# nrf54h20_engb_application register map
Vendor: Nordic Semiconductor; Series: nRF54h; File version: 1
CPU: CM33 r0p4, little endian, MPU, FPU, 3 interrupt priority bits, 480 interrupts, 8 SAU regions
Registers are 32-bit, read-write, reset 0x0 unless marked. A register's access mark holds for its fields unless they carry their own. Offsets are from the block's base; [hi:lo] are bit positions; lines under a group give offsets from that group; {n}, {i} and the like mark numbered series; 'fields as' and 'values as' point back to an identical list.

## GLOBAL_SPIS120_NS — SPI Slave 0
Base 0x4F8E5000
Same registers: GLOBAL_SPIS130_NS 0x4F9A5000 (alternate view of GLOBAL_SPIM130_NS), GLOBAL_SPIS131_NS 0x4F9A6000 (alternate view of GLOBAL_SPIM131_NS), GLOBAL_SPIS132_NS 0x4F9B5000 (alternate view of GLOBAL_SPIM132_NS), GLOBAL_SPIS133_NS 0x4F9B6000 (alternate view of GLOBAL_SPIM133_NS), GLOBAL_SPIS134_NS 0x4F9C5000 (alternate view of GLOBAL_SPIM134_NS), GLOBAL_SPIS135_NS 0x4F9C6000 (alternate view of GLOBAL_SPIM135_NS), GLOBAL_SPIS136_NS 0x4F9D5000 (alternate view of GLOBAL_SPIM136_NS), GLOBAL_SPIS137_NS 0x4F9D6000 (alternate view of GLOBAL_SPIM137_NS), GLOBAL_SPIS120_S 0x5F8E5000, GLOBAL_SPIS130_S 0x5F9A5000 (alternate view of GLOBAL_SPIM130_S), GLOBAL_SPIS131_S 0x5F9A6000 (alternate view of GLOBAL_SPIM131_S), GLOBAL_SPIS132_S 0x5F9B5000 (alternate view of GLOBAL_SPIM132_S), GLOBAL_SPIS133_S 0x5F9B6000 (alternate view of GLOBAL_SPIM133_S), GLOBAL_SPIS134_S 0x5F9C5000 (alternate view of GLOBAL_SPIM134_S), GLOBAL_SPIS135_S 0x5F9C6000 (alternate view of GLOBAL_SPIM135_S), GLOBAL_SPIS136_S 0x5F9D5000 (alternate view of GLOBAL_SPIM136_S), GLOBAL_SPIS137_S 0x5F9D6000 (alternate view of GLOBAL_SPIM137_S)
0x14 TASKS_ACQUIRE wo — Acquire SPI semaphore
  [0] TASKS_ACQUIRE
    1=Trigger task
0x18 TASKS_RELEASE wo — Release SPI semaphore, enabling the SPI slave to acquire it
  [0] TASKS_RELEASE
    1=Trigger task
0x28 TASKS_DMA group — Peripheral tasks.
  0x08 RX group — Peripheral tasks.
    {0x0+4k} ENABLEMATCH[{k}] (k=0..3) wo — Description collection: Enables the MATCH[n] event by setting the ENABLE[n] bit in the CONFIG register.
      [0] ENABLEMATCH — Enables the MATCH[n] event by setting the ENABLE[n] bit in the CONFIG register.
        1=Trigger task
    {0x10+4k} DISABLEMATCH[{k}] (k=0..3) wo — Description collection: Disables the MATCH[n] event by clearing the ENABLE[n] bit in the CONFIG register.
      [0] DISABLEMATCH — Disables the MATCH[n] event by clearing the ENABLE[n] bit in the CONFIG register.
        1=Trigger task
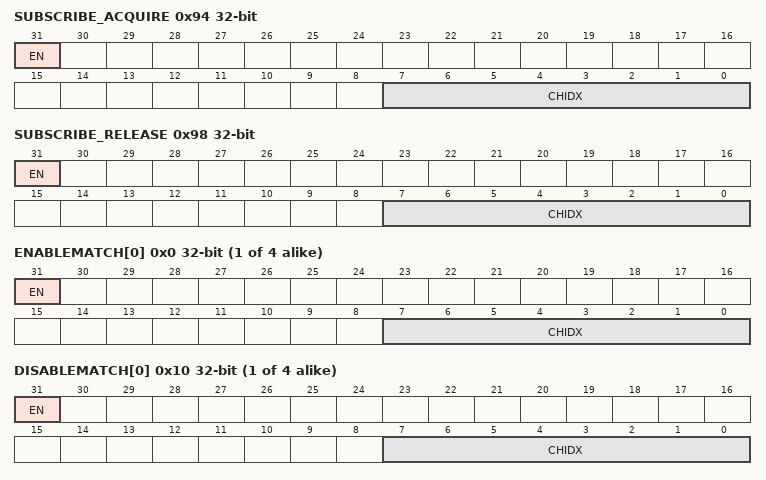
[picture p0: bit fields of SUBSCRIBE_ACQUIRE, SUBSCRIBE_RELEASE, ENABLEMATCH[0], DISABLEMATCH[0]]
0x94 SUBSCRIBE_ACQUIRE — Subscribe configuration for task ACQUIRE
  [31] EN
    0=Disabled (Disable subscription); 1=Enabled (Enable subscription)
  [7:0] CHIDX — DPPI channel that task ACQUIRE will subscribe to
0x98 SUBSCRIBE_RELEASE — Subscribe configuration for task RELEASE
  [31] EN
    values as SUBSCRIBE_ACQUIRE.EN
  [7:0] CHIDX — DPPI channel that task RELEASE will subscribe to
0xA8 SUBSCRIBE_DMA group — Subscribe configuration for tasks
  0x08 RX group — Subscribe configuration for tasks
    {0x0+4k} ENABLEMATCH[{k}] (k=0..3) — Description collection: Subscribe configuration for task ENABLEMATCH[n]
      [31] EN
        values as SUBSCRIBE_ACQUIRE.EN
      [7:0] CHIDX — DPPI channel that task ENABLEMATCH[n] will subscribe to
    {0x10+4k} DISABLEMATCH[{k}] (k=0..3) — Description collection: Subscribe configuration for task DISABLEMATCH[n]
      [31] EN
        values as SUBSCRIBE_ACQUIRE.EN
      [7:0] CHIDX — DPPI channel that task DISABLEMATCH[n] will subscribe to
0x100 EVENTS_STARTED — Chip select line (CSN) has gone active (low)
  [0] EVENTS_STARTED
    0=NotGenerated (Event not generated); 1=Generated (Event generated)
0x104 EVENTS_END — Granted transaction completed Chip select line (CSN) has gone inactive (high)
  [0] EVENTS_END
    values as EVENTS_STARTED.EVENTS_STARTED
0x118 EVENTS_ACQUIRED — Semaphore acquired
  [0] EVENTS_ACQUIRED
    values as EVENTS_STARTED.EVENTS_STARTED
0x14C EVENTS_DMA group — Peripheral events.
  0x00 RX group — Peripheral events.
    0x00 END — Generated after all MAXCNT bytes have been transferred Equivalent to eventDmaEnd[Channel]
      [0] END
        values as EVENTS_STARTED.EVENTS_STARTED
    0x04 READY — Generated when EasyDMA has buffered the .PTR and .MAXCNT registers for the channel, allowing them to be written to prepare for the next sequence.
      [0] READY
        values as EVENTS_STARTED.EVENTS_STARTED
    0x08 BUSERROR — An error occured during the bus transfer. This event is generated on an AHB / AXI error response.
      [0] BUSERROR
        values as EVENTS_STARTED.EVENTS_STARTED
    {0xC+4k} MATCH[{k}] (k=0..3) — Description collection: Pattern match is detected on the DMA data bus.
      [0] MATCH — Pattern match is detected on the DMA data bus.
        values as EVENTS_STARTED.EVENTS_STARTED
  0x1C TX group — Peripheral events.
    0x00 END — Generated after all MAXCNT bytes have been transferred Equivalent to eventDmaEnd[Channel]
      fields as EVENTS_DMA.RX.END
    0x04 READY — Generated when EasyDMA has buffered the .PTR and .MAXCNT registers for the channel, allowing them to be written to prepare for the next sequence.
      fields as EVENTS_DMA.RX.READY
    0x08 BUSERROR — An error occured during the bus transfer. This event is generated on an AHB / AXI error response.
      fields as EVENTS_DMA.RX.BUSERROR
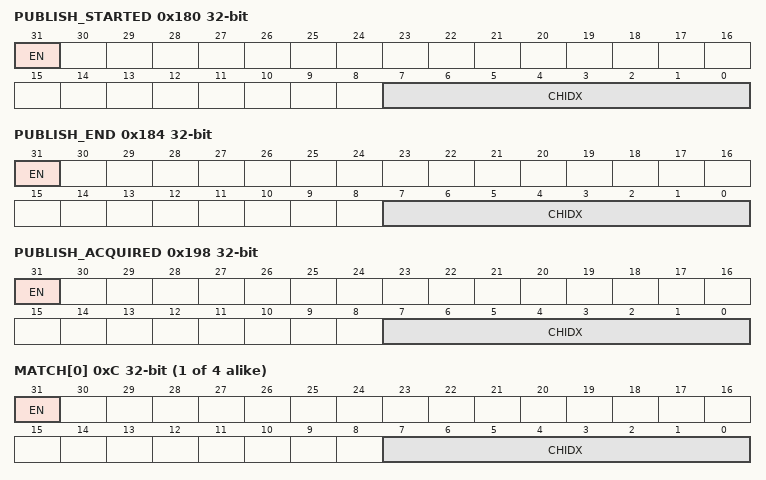
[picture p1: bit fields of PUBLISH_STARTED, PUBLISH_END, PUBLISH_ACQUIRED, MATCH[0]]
0x180 PUBLISH_STARTED — Publish configuration for event STARTED
  [31] EN
    0=Disabled (Disable publishing); 1=Enabled (Enable publishing)
  [7:0] CHIDX — DPPI channel that event STARTED will publish to
0x184 PUBLISH_END — Publish configuration for event END
  [31] EN
    values as PUBLISH_STARTED.EN
  [7:0] CHIDX — DPPI channel that event END will publish to
0x198 PUBLISH_ACQUIRED — Publish configuration for event ACQUIRED
  [31] EN
    values as PUBLISH_STARTED.EN
  [7:0] CHIDX — DPPI channel that event ACQUIRED will publish to
0x1CC PUBLISH_DMA group — Publish configuration for events
  0x00 RX group — Publish configuration for events
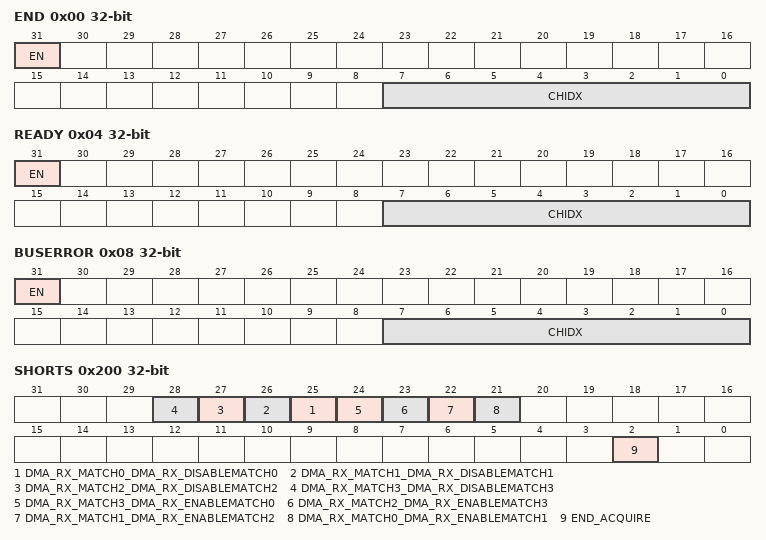
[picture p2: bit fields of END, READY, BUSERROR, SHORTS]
    0x00 END — Publish configuration for event END
      fields as PUBLISH_END
    0x04 READY — Publish configuration for event READY
      [31] EN
        values as PUBLISH_STARTED.EN
      [7:0] CHIDX — DPPI channel that event READY will publish to
    0x08 BUSERROR — Publish configuration for event BUSERROR
      [31] EN
        values as PUBLISH_STARTED.EN
      [7:0] CHIDX — DPPI channel that event BUSERROR will publish to
    {0xC+4k} MATCH[{k}] (k=0..3) — Description collection: Publish configuration for event MATCH[n]
      [31] EN
        values as PUBLISH_STARTED.EN
      [7:0] CHIDX — DPPI channel that event MATCH[n] will publish to
  0x1C TX group — Publish configuration for events
    0x00 END — Publish configuration for event END
      fields as PUBLISH_END
    0x04 READY — Publish configuration for event READY
      fields as PUBLISH_DMA.RX.READY
    0x08 BUSERROR — Publish configuration for event BUSERROR
      fields as PUBLISH_DMA.RX.BUSERROR
0x200 SHORTS — Shortcuts between local events and tasks
  [all] fields
    0=Disabled (Disable shortcut); 1=Enabled (Enable shortcut)
  [n+25] DMA_RX_MATCH{n}_DMA_RX_DISABLEMATCH{n} (n=0..3) — Shortcut between event DMA.RX.MATCH[n] and task DMA.RX.DISABLEMATCH[n]
  [24] DMA_RX_MATCH3_DMA_RX_ENABLEMATCH0 — Shortcut between event DMA.RX.MATCH[n] and task DMA.RX.ENABLEMATCH[0] Allows daisy-chaining match events.
  [23] DMA_RX_MATCH2_DMA_RX_ENABLEMATCH3 — Shortcut between event DMA.RX.MATCH[n] and task DMA.RX.ENABLEMATCH[3] Allows daisy-chaining match events.
  [22] DMA_RX_MATCH1_DMA_RX_ENABLEMATCH2 — Shortcut between event DMA.RX.MATCH[n] and task DMA.RX.ENABLEMATCH[2] Allows daisy-chaining match events.
  [21] DMA_RX_MATCH0_DMA_RX_ENABLEMATCH1 — Shortcut between event DMA.RX.MATCH[n] and task DMA.RX.ENABLEMATCH[1] Allows daisy-chaining match events.
  [2] END_ACQUIRE — Shortcut between event END and task ACQUIRE
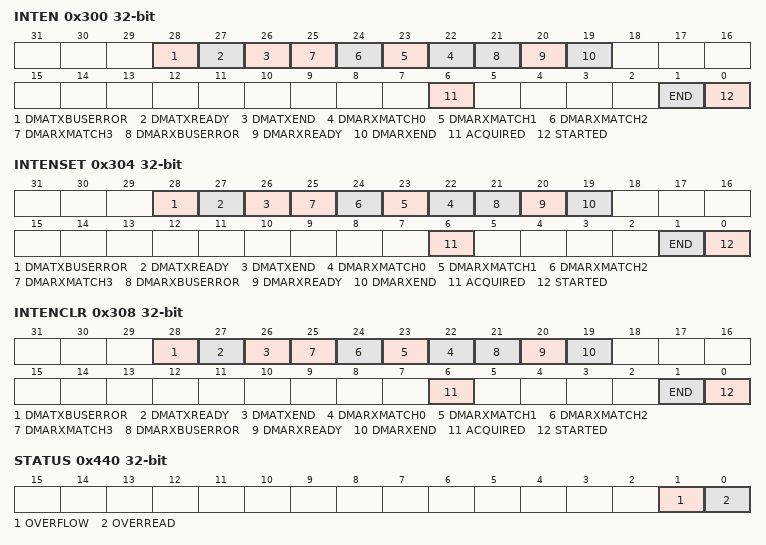
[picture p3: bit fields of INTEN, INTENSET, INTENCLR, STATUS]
0x300 INTEN — Enable or disable interrupt
  [all] fields
    0=Disabled; 1=Enabled
  [28] DMATXBUSERROR — Enable or disable interrupt for event DMATXBUSERROR
  [27] DMATXREADY — Enable or disable interrupt for event DMATXREADY
  [26] DMATXEND — Enable or disable interrupt for event DMATXEND
  [n+22] DMARXMATCH{n} (n=0..3) — Enable or disable interrupt for event DMARXMATCH[{n}]
  [21] DMARXBUSERROR — Enable or disable interrupt for event DMARXBUSERROR
  [20] DMARXREADY — Enable or disable interrupt for event DMARXREADY
  [19] DMARXEND — Enable or disable interrupt for event DMARXEND
  [6] ACQUIRED — Enable or disable interrupt for event ACQUIRED
  [1] END — Enable or disable interrupt for event END
  [0] STARTED — Enable or disable interrupt for event STARTED
0x304 INTENSET — Enable interrupt
  [all] fields
    on read: 0=Disabled (Read: Disabled); 1=Enabled (Read: Enabled) | on write: 1=Set (Enable)
  [28] DMATXBUSERROR — Write '1' to enable interrupt for event DMATXBUSERROR
  [27] DMATXREADY — Write '1' to enable interrupt for event DMATXREADY
  [26] DMATXEND — Write '1' to enable interrupt for event DMATXEND
  [n+22] DMARXMATCH{n} (n=0..3) — Write '1' to enable interrupt for event DMARXMATCH[{n}]
  [21] DMARXBUSERROR — Write '1' to enable interrupt for event DMARXBUSERROR
  [20] DMARXREADY — Write '1' to enable interrupt for event DMARXREADY
  [19] DMARXEND — Write '1' to enable interrupt for event DMARXEND
  [6] ACQUIRED — Write '1' to enable interrupt for event ACQUIRED
  [1] END — Write '1' to enable interrupt for event END
  [0] STARTED — Write '1' to enable interrupt for event STARTED
0x308 INTENCLR — Disable interrupt
  [all] fields
    on read: 0=Disabled (Read: Disabled); 1=Enabled (Read: Enabled) | on write: 1=Clear (Disable)
  [28] DMATXBUSERROR — Write '1' to disable interrupt for event DMATXBUSERROR
  [27] DMATXREADY — Write '1' to disable interrupt for event DMATXREADY
  [26] DMATXEND — Write '1' to disable interrupt for event DMATXEND
  [n+22] DMARXMATCH{n} (n=0..3) — Write '1' to disable interrupt for event DMARXMATCH[{n}]
  [21] DMARXBUSERROR — Write '1' to disable interrupt for event DMARXBUSERROR
  [20] DMARXREADY — Write '1' to disable interrupt for event DMARXREADY
  [19] DMARXEND — Write '1' to disable interrupt for event DMARXEND
  [6] ACQUIRED — Write '1' to disable interrupt for event ACQUIRED
  [1] END — Write '1' to disable interrupt for event END
  [0] STARTED — Write '1' to disable interrupt for event STARTED
0x400 SEMSTAT ro reset 0x1 — Semaphore status register
  [1:0] SEMSTAT — Semaphore status
    0=Free (Semaphore is free); 1=CPU (Semaphore is assigned to CPU); 2=SPIS (Semaphore is assigned to SPI slave); 3=CPUPending (Semaphore is assigned to SPI but a handover to the CPU is pending)
0x440 STATUS — Status from last transaction
  [1] OVERFLOW — RX buffer overflow detected, and prevented
    on read: 0=NotPresent (Read: error not present); 1=Present (Read: error present) | on write: 1=Clear (Write: clear error on writing '1')
  [0] OVERREAD — TX buffer over-read detected, and prevented
    values as OVERFLOW
0x500 ENABLE — Enable SPI slave
  [3:0] ENABLE — Enable or disable SPI slave
    0=Disabled (Disable SPI slave); 2=Enabled (Enable SPI slave)
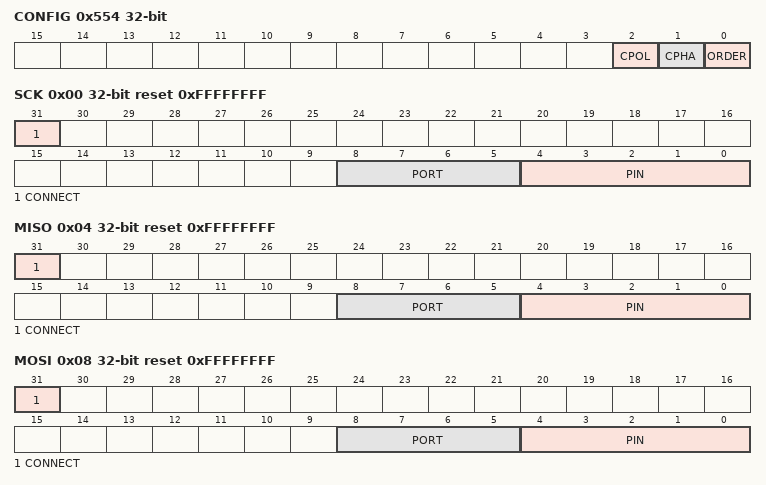
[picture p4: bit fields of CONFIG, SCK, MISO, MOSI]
0x554 CONFIG — Configuration register
  [2] CPOL — Serial clock (SCK) polarity
    0=ActiveHigh; 1=ActiveLow
  [1] CPHA — Serial clock (SCK) phase
    0=Leading (Sample on leading edge of clock, shift serial data on trailing edge); 1=Trailing (Sample on trailing edge of clock, shift serial data on leading edge)
  [0] ORDER — Bit order
    0=MsbFirst (Most significant bit shifted out first); 1=LsbFirst (Least significant bit shifted out first)
0x55C DEF — Default character. Character clocked out in case of an ignored transaction.
  [7:0] DEF
0x5C0 ORC — Over-read character
  [7:0] ORC — Over-read character. Character clocked out after an over-read of the transmit buffer.
0x600 PSEL group — Unspecified
  0x00 SCK reset 0xFFFFFFFF — Pin select for SCK
    [31] CONNECT — Connection
      1=Disconnected; 0=Connected
    [8:5] PORT — Port number
    [4:0] PIN — Pin number
  0x04 MISO reset 0xFFFFFFFF — Pin select for MISO signal
    fields as PSEL.SCK
  0x08 MOSI reset 0xFFFFFFFF — Pin select for MOSI signal
    fields as PSEL.SCK
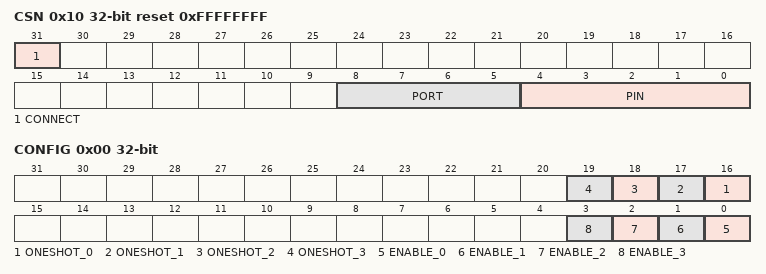
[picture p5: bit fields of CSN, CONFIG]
  0x10 CSN reset 0xFFFFFFFF — Pin select for CSN signal
    fields as PSEL.SCK
0x700 DMA group — Unspecified
  0x00 RX group — Unspecified
    0x00 ENABLE — Register doesn't do anything. Can be written and read, but has no functionality attached.
      [0] ENABLE
        0=Disabled; 1=Enabled
    0x04 PTR — RAM buffer start address
      [31:0] PTR — RAM buffer start address for this EasyDMA channel. This address is a word aligned Data RAM address.
    0x08 MAXCNT — Maximum number of bytes in channel buffer
      [15:0] MAXCNT
    0x0C AMOUNT ro — Number of bytes transferred in the last transaction, updated after the END event. Also updated after each MATCH event.
      [15:0] AMOUNT — Number of bytes transferred in the last transaction. In case of NACK error, includes the NACK'ed byte.
    0x10 CURRENTAMOUNT ro — Number of bytes transferred in the current transaction
      [15:0] AMOUNT — Number of bytes transferred in the current transaction. Continuously updated. Updated when data leaves the internal FIFO and is transferred to the destination.
    0x14 LIST — EasyDMA list type
      [2:0] TYPE — List type
        0=Disabled (Disable EasyDMA list); 1=ArrayList (Use array list)
    0x1C TERMINATEONBUSERROR — Terminate the transaction if a BUSERROR event is detected.
      [0] ENABLE
        0=Disabled; 1=Enabled
    0x20 BUSERRORADDRESS ro — Address of transaction that generated the last BUSERROR event.
      [31:0] ADDRESS
    0x24 MATCH group — Registers to control the behavior of the pattern matcher engine
      0x00 CONFIG — Configure individual match events
        [n+16] ONESHOT_{n} (n=0..3) — Configure match filter {n} as one-shot or sticky
          0=Continuous (Match filter stays enabled until disabled by task); 1=Oneshot (Match filter stays enabled until next data word is received)
        [n] ENABLE_{n} (n=0..3) — Enable match filter {n}
          0=Disabled (Match filter disabled); 1=Enabled (Match filter enabled)
      {0x4+4l} CANDIDATE[{l}] (l=0..3) — Description collection: The data to look for - any match will trigger the MATCH[n] event, if enabled.
        [31:0] DATA — Data to look for
  0x38 TX group — Unspecified
    0x00 ENABLE — Register doesn't do anything. Can be written and read, but has no functionality attached.
      [0] ENABLE
        0=Disabled; 1=Enabled
    0x04 PTR — RAM buffer start address
      fields as DMA.RX.PTR
    0x08 MAXCNT — Maximum number of bytes in channel buffer
      [15:0] MAXCNT
    0x0C AMOUNT ro — Number of bytes transferred in the last transaction, updated after the END event. Also updated after each MATCH event.
      fields as DMA.RX.AMOUNT
    0x10 CURRENTAMOUNT ro — Number of bytes transferred in the current transaction
      fields as DMA.RX.CURRENTAMOUNT
    0x14 LIST — EasyDMA list type
      fields as DMA.RX.LIST
    0x1C TERMINATEONBUSERROR — Terminate the transaction if a BUSERROR event is detected.
      [0] ENABLE
        0=Disabled; 1=Enabled
    0x20 BUSERRORADDRESS ro — Address of transaction that generated the last BUSERROR event.
      [31:0] ADDRESS
